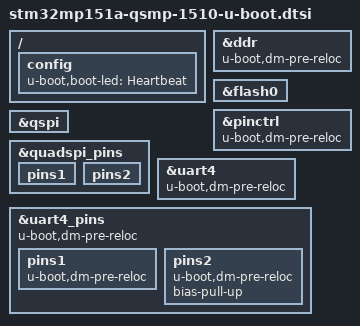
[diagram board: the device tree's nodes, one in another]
// SPDX-License-Identifier: GPL-2.0 OR BSD-3-Clause
/*
 * Copyright (C) 2020: Lothar Waßmann <LW@KARO-electronics.de>
 */

#include <dt-bindings/clock/stm32mp1-clksrc.h>
#include "stm32mp15-u-boot.dtsi"
#include "stm32mp15-ddr.dtsi"
#include "stm32mp15-qsmp-u-boot.dtsi"

/ {
	config {
		u-boot,boot-led = "Heartbeat";
	};
};

&ddr {
	u-boot,dm-pre-reloc;
};

&flash0 {
	u-boot,dm-spl;
};

&pinctrl {
	u-boot,dm-pre-reloc;
};

&qspi {
	u-boot,dm-spl;
};

&quadspi_pins {
	u-boot,dm-spl;

	pins1 {
		u-boot,dm-spl;
	};

	pins2 {
		u-boot,dm-spl;
	};
};

&uart4 {
	u-boot,dm-pre-reloc;
};

&uart4_pins {
	u-boot,dm-pre-reloc;

	pins1 {
		u-boot,dm-pre-reloc;
	};

	pins2 {
		u-boot,dm-pre-reloc;
		/* pull-up on rx to avoid floating level */
		bias-pull-up;
	};
};
